# WBZ450 register map
Vendor: Microchip
Registers are 32-bit, read-write, reset 0x0 unless marked. A register's access mark holds for its fields unless they carry their own. Addresses are absolute, and some are shared; only a register's first bit layout is shown; [hi:lo] are bit positions; {n}, {i} and the like mark numbered series; 'fields as' and 'values as' point back to an identical list.

## FREQM
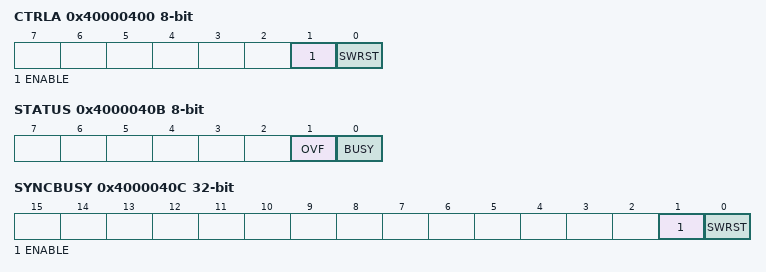
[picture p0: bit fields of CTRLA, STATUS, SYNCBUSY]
0x40000400 CTRLA 8-bit
  [1] ENABLE
  [0] SWRST — Software Reset
0x40000401 CTRLB 8-bit wo
  [0] START — Start Measurement
0x40000402 CFGA 16-bit
  [7:0] REFNUM — Number of Reference Clock Cycles
0x40000408 INTENCLR 8-bit
  [0] DONE — Measurement Done Interrupt Enable
0x40000409 INTENSET 8-bit
  [0] DONE — Measurement Done Interrupt Enable
0x4000040A INTFLAG 8-bit
  [0] DONE — Measurement Done
0x4000040B STATUS 8-bit
  [1] OVF — Sticky Count Value Overflow
  [0] BUSY — FREQM Status
0x4000040C SYNCBUSY ro
  [1] ENABLE
  [0] SWRST — Software Reset
0x40000410 VALUE ro
  [23:0] VALUE — Measurement Value

## EIC
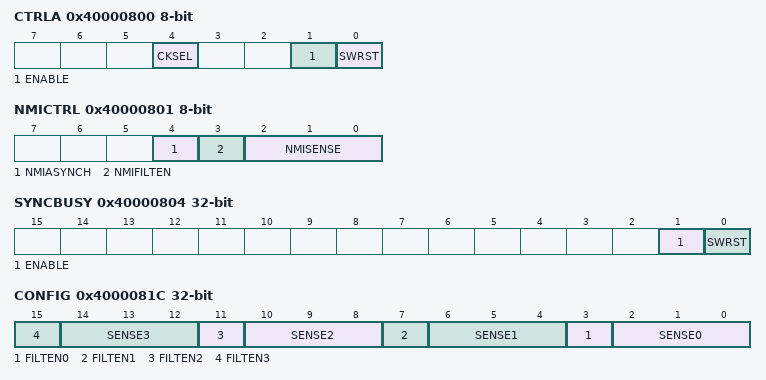
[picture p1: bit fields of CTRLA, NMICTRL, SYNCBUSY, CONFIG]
0x40000800 CTRLA 8-bit
  [4] CKSEL — Clock Selection
    0=CLK_GCLK (Clocked by GCLK); 1=CLK_ULP32K (Clocked by ULP32K)
  [1] ENABLE
  [0] SWRST — Software Reset
0x40000801 NMICTRL 8-bit
  [4] NMIASYNCH — Asynchronous Edge Detection Mode
    0=SYNC (Edge detection is clock synchronously operated); 1=ASYNC (Edge detection is clock asynchronously operated)
  [3] NMIFILTEN — Non-Maskable Interrupt Filter Enable
  [2:0] NMISENSE — Non-Maskable Interrupt Sense Configuration
    0=NONE (No detection); 1=RISE (Rising-edge detection); 2=FALL (Falling-edge detection); 3=BOTH (Both-edges detection); 4=HIGH (High-level detection); 5=LOW (Low-level detection)
0x40000802 NMIFLAG 16-bit
  [0] NMI — Non-Maskable Interrupt
0x40000804 SYNCBUSY ro
  [1] ENABLE — Enable Synchronization Busy Status
  [0] SWRST — Software Reset Synchronization Busy Status
0x40000808 EVCTRL
  [3:0] EXTINTEO — External Interrupt Event Output Enable
0x4000080C INTENCLR
  [3:0] EXTINT — External Interrupt Enable
0x40000810 INTENSET
  [3:0] EXTINT — External Interrupt Enable
0x40000814 INTFLAG
  [3:0] EXTINT — External Interrupt
0x40000818 ASYNCH
  [3:0] ASYNCH — Asynchronous Edge Detection Mode
    values as NMICTRL.NMIASYNCH
0x4000081C CONFIG
  [4n+3] FILTEN{n} (n=0..3) — Filter Enable {n}
  [4n+2:4n] SENSE{n} (n=0..3) — Input Sense Configuration {n}
    0=NONE (No detection); 1=RISE (Rising edge detection); 2=FALL (Falling edge detection); 3=BOTH (Both edges detection); 4=HIGH (High level detection); 5=LOW (Low level detection)
0x40000830 DEBOUNCEN
  [3:0] DEBOUNCEN — Debouncer Enable
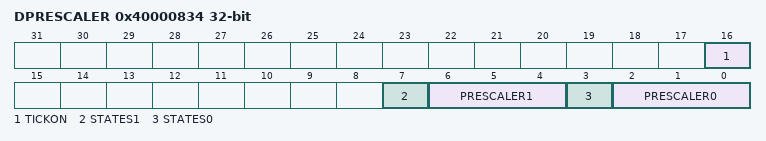
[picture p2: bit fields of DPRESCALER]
0x40000834 DPRESCALER
  [16] TICKON — Pin Sampler frequency selection
    0=CLK_GCLK_EIC (Clocked by GCLK); 1=CLK_LFREQ (Clocked by Low Frequency Clock)
  [7] STATES1 — Debouncer number of states
    0=LFREQ3 (3 low frequency samples); 1=LFREQ7 (7 low frequency samples)
  [6:4] PRESCALER1 — Debouncer Prescaler
    0=DIV2 (EIC clock divided by 2); 1=DIV4 (EIC clock divided by 4); 2=DIV8 (EIC clock divided by 8); 3=DIV16 (EIC clock divided by 16); 4=DIV32 (EIC clock divided by 32); 5=DIV64 (EIC clock divided by 64); 6=DIV128 (EIC clock divided by 128); 7=DIV256 (EIC clock divided by 256)
  [3] STATES0 — Debouncer number of states
    values as STATES1
  [2:0] PRESCALER0 — Debouncer Prescaler
    values as PRESCALER1
0x40000838 PINSTATE ro
  [3:0] PINSTATE

## TC0
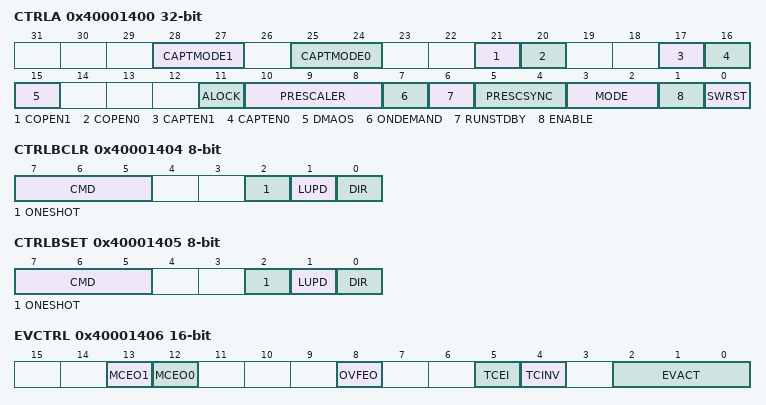
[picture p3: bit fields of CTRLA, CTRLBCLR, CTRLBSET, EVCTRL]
0x40001400 CTRLA
  [28:27] CAPTMODE1 — Capture mode Channel 1
    0=DEFAULT (Default capture); 1=CAPTMIN (Minimum capture); 2=CAPTMAX (Maximum capture)
  [25:24] CAPTMODE0 — Capture Mode Channel 0
    values as CAPTMODE1
  [21] COPEN1 — Capture On Pin 1 Enable
  [20] COPEN0 — Capture On Pin 0 Enable
  [17] CAPTEN1 — Capture Channel 1 Enable
  [16] CAPTEN0 — Capture Channel 0 Enable
  [15] DMAOS — DMA One Shot
  [11] ALOCK — Auto Lock
  [10:8] PRESCALER
    0=DIV1 (Prescaler: GCLK_TC); 1=DIV2 (Prescaler: GCLK_TC/2); 2=DIV4 (Prescaler: GCLK_TC/4); 3=DIV8 (Prescaler: GCLK_TC/8); 4=DIV16 (Prescaler: GCLK_TC/16); 5=DIV64 (Prescaler: GCLK_TC/64); 6=DIV256 (Prescaler: GCLK_TC/256); 7=DIV1024 (Prescaler: GCLK_TC/1024)
  [7] ONDEMAND — Clock On Demand
  [6] RUNSTDBY — Run during Standby
  [5:4] PRESCSYNC — Prescaler and Counter Synchronization
    0=GCLK (Reload or reset the counter on next generic clock); 1=PRESC (Reload or reset the counter on next prescaler clock); 2=RESYNC (Reload or reset the counter on next generic clock and reset the prescaler counter)
  [3:2] MODE — Timer Counter Mode
    0=COUNT16 (Counter in 16-bit mode); 1=COUNT8 (Counter in 8-bit mode); 2=COUNT32 (Counter in 32-bit mode)
  [1] ENABLE
  [0] SWRST — Software Reset
0x40001404 CTRLBCLR 8-bit
  [7:5] CMD — Command
    0=NONE (No action); 1=RETRIGGER (Force a start, restart or retrigger); 2=STOP (Force a stop); 3=UPDATE (Force update of double-buffered register); 4=READSYNC (Force a read synchronization of COUNT); 5=DMAOS (One-shot DMA trigger)
  [2] ONESHOT — One-Shot on Counter
  [1] LUPD — Lock Update
  [0] DIR — Counter Direction
0x40001405 CTRLBSET 8-bit
  fields as CTRLBCLR
0x40001406 EVCTRL 16-bit
  [13] MCEO1 — MC Event Output Enable 1
  [12] MCEO0 — MC Event Output Enable 0
  [8] OVFEO — Event Output Enable
  [5] TCEI — TC Event Enable
  [4] TCINV — TC Event Input Polarity
  [2:0] EVACT — Event Action
    0=OFF (Event action disabled); 1=RETRIGGER (Start, restart or retrigger TC on event); 2=COUNT (Count on event); 3=START (Start TC on event); 4=STAMP (Time stamp capture); 5=PPW (Period catured in CC0, pulse width in CC1); 6=PWP (Period catured in CC1, pulse width in CC0); 7=PW (Pulse width capture)
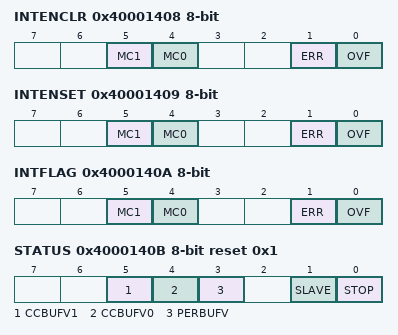
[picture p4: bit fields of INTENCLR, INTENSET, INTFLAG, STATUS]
0x40001408 INTENCLR 8-bit
  [5] MC1 — MC Interrupt Disable 1
  [4] MC0 — MC Interrupt Disable 0
  [1] ERR — ERR Interrupt Disable
  [0] OVF — OVF Interrupt Disable
0x40001409 INTENSET 8-bit
  [5] MC1 — MC Interrupt Enable 1
  [4] MC0 — MC Interrupt Enable 0
  [1] ERR — ERR Interrupt Enable
  [0] OVF — OVF Interrupt Enable
0x4000140A INTFLAG 8-bit
  [5] MC1 — MC Interrupt Flag 1
  [4] MC0 — MC Interrupt Flag 0
  [1] ERR — ERR Interrupt Flag
  [0] OVF — OVF Interrupt Flag
0x4000140B STATUS 8-bit reset 0x1
  [5] CCBUFV1 — Compare channel buffer 1 valid
  [4] CCBUFV0 — Compare channel buffer 0 valid
  [3] PERBUFV — Synchronization Busy Status
  [1] SLAVE — Slave Status Flag
  [0] STOP — Stop Status Flag
0x4000140C WAVE 8-bit
  [1:0] WAVEGEN — Waveform Generation Mode
    0=NFRQ (Normal frequency); 1=MFRQ (Match frequency); 2=NPWM (Normal PWM); 3=MPWM (Match PWM)
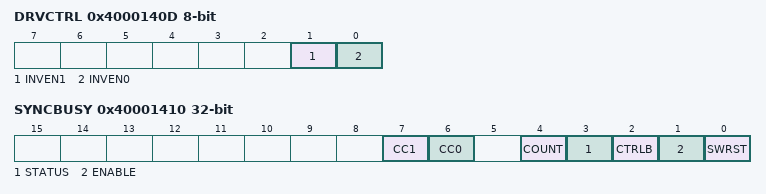
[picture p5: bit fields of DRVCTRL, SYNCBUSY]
0x4000140D DRVCTRL 8-bit
  [1] INVEN1 — Output Waveform Invert Enable 1
  [0] INVEN0 — Output Waveform Invert Enable 0
0x4000140F DBGCTRL 8-bit
  [0] DBGRUN — Run During Debug
0x40001410 SYNCBUSY ro
  [7] CC1 — Compare Channel 1
  [6] CC0 — Compare Channel 0
  [4] COUNT — Counter
  [3] STATUS
  [2] CTRLB
  [1] ENABLE
  [0] SWRST
